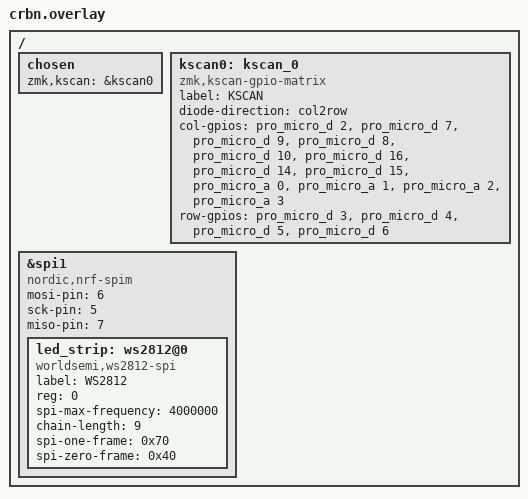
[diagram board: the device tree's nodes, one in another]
#include <dt-bindings/zmk/matrix_transform.h>
/ {
	chosen {
		zmk,kscan = &kscan0;
	};

	kscan0: kscan_0 {
		compatible = "zmk,kscan-gpio-matrix";
		label = "KSCAN";
		diode-direction = "col2row";

		col-gpios
			= <&pro_micro_d 2 GPIO_ACTIVE_HIGH>
			, <&pro_micro_d 7 GPIO_ACTIVE_HIGH>
			, <&pro_micro_d 9 GPIO_ACTIVE_HIGH>
			, <&pro_micro_d 8 GPIO_ACTIVE_HIGH>
			, <&pro_micro_d 10 GPIO_ACTIVE_HIGH>
			, <&pro_micro_d 16 GPIO_ACTIVE_HIGH>
			, <&pro_micro_d 14 GPIO_ACTIVE_HIGH>
			, <&pro_micro_d 15 GPIO_ACTIVE_HIGH>
			, <&pro_micro_a 0 GPIO_ACTIVE_HIGH>
			, <&pro_micro_a 1 GPIO_ACTIVE_HIGH>
			, <&pro_micro_a 2 GPIO_ACTIVE_HIGH>
			, <&pro_micro_a 3 GPIO_ACTIVE_HIGH>
			;

		row-gpios
			= <&pro_micro_d 3 (GPIO_ACTIVE_HIGH | GPIO_PULL_DOWN)>
			, <&pro_micro_d 4 (GPIO_ACTIVE_HIGH | GPIO_PULL_DOWN)>
			, <&pro_micro_d 5 (GPIO_ACTIVE_HIGH | GPIO_PULL_DOWN)>
			, <&pro_micro_d 6 (GPIO_ACTIVE_HIGH | GPIO_PULL_DOWN)>
			;
	};

	&spi1 {
	  compatible = "nordic,nrf-spim";
	  status = "okay";
	  mosi-pin = <6>;
	  // Unused pins, needed for SPI definition, but not used by the ws2812 driver itself.
	  sck-pin = <5>;
	  miso-pin = <7>;

	  led_strip: ws2812@0 {
	    compatible = "worldsemi,ws2812-spi";
	    label = "WS2812";

	    /* SPI */
	    reg = <0>; /* ignored, but necessary for SPI bindings */
	    spi-max-frequency = <4000000>;

	    /* WS2812 */
	    chain-length = <9>; /* number of LEDs */
	    spi-one-frame = <0x70>;
	    spi-zero-frame = <0x40>;
	  };
	};
};
